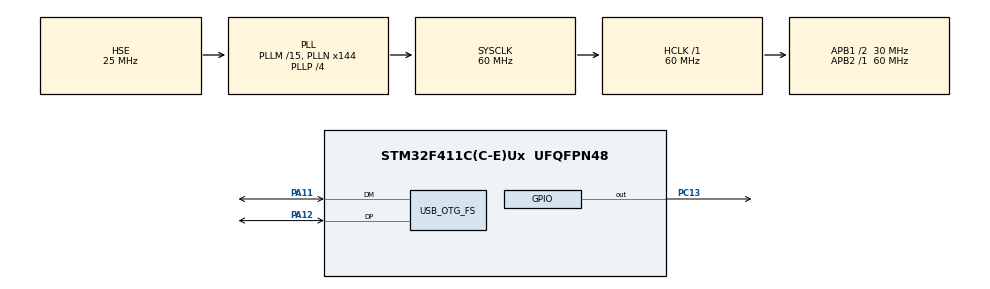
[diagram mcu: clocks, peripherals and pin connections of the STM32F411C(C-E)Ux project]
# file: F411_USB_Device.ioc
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Mcu.Family=STM32F4
Mcu.Name=STM32F411C(C-E)Ux
Mcu.Package=UFQFPN48
NVIC.OTG_FS_IRQn=true\:0\:0\:false\:false\:true\:false\:true\:true
NVIC.PriorityGroup=NVIC_PRIORITYGROUP_4
PA11.Mode=Device_Only
PA11.Signal=USB_OTG_FS_DM
PA12.Mode=Device_Only
PA12.Signal=USB_OTG_FS_DP
PC13-ANTI_TAMP.Signal=GPIO_Output
PH0\ -\ OSC_IN.Mode=HSE-External-Oscillator
PH0\ -\ OSC_IN.Signal=RCC_OSC_IN
PH1\ -\ OSC_OUT.Mode=HSE-External-Oscillator
PH1\ -\ OSC_OUT.Signal=RCC_OSC_OUT
ProjectManager.HeapSize=0x600
ProjectManager.StackSize=0x400
ProjectManager.TargetToolchain=STM32CubeIDE
RCC.48MHZClocksFreq_Value=48000000
RCC.AHBFreq_Value=60000000
RCC.APB1CLKDivider=RCC_HCLK_DIV2
RCC.APB1Freq_Value=30000000
RCC.APB1TimFreq_Value=60000000
RCC.APB2Freq_Value=60000000
RCC.APB2TimFreq_Value=60000000
RCC.CortexFreq_Value=60000000
RCC.HCLKFreq_Value=60000000
RCC.HSE_VALUE=25000000
RCC.HSI_VALUE=16000000
RCC.LSE_VALUE=32768
RCC.PLLM=15
RCC.PLLN=144
RCC.PLLP=RCC_PLLP_DIV4
RCC.PLLQ=5
RCC.SYSCLKFreq_VALUE=60000000
RCC.SYSCLKSource=RCC_SYSCLKSOURCE_PLLCLK
RCC.VCOOutputFreq_Value=240000000
USB_DEVICE.CLASS_NAME_FS=CDC
USB_DEVICE.VirtualMode=Cdc
USB_DEVICE.VirtualModeFS=Cdc_FS
USB_OTG_FS.VirtualMode=Device_Only
VP_USB_DEVICE_VS_USB_DEVICE_CDC_FS.Mode=CDC_FS
board=custom

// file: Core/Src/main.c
/* USER CODE BEGIN Header */
/**
 ******************************************************************************
 * @file           : main.c
 * @brief          : Main program body
 ******************************************************************************
 * @attention
 *
 * Copyright (c) 2025 STMicroelectronics.
 * All rights reserved.
 *
 * This software is licensed under terms that can be found in the LICENSE file
 * in the root directory of this software component.
 * If no LICENSE file comes with this software, it is provided AS-IS.
 *
 ******************************************************************************
 */
/* USER CODE END Header */
#include "main.h"
#include "usb_device.h"
#include "gpio.h"

/* USER CODE BEGIN Includes */
#include <string.h>
#include "usbd_cdc_if.h"
/* USER CODE END Includes */

void SystemClock_Config(void);

/* USER CODE BEGIN 0 */

/**********************************************
 * Fonction de traitement des données reçues
 **********************************************/
void My_USB_DataReceived_Handler(uint8_t *data, uint32_t length) {

	// Exemple : On retransmets les données.
	CDC_Transmit_FS(data, length);
}
/* USER CODE END 0 */

int main(void)
{

  /* MCU Configuration--------------------------------------------------------*/

  /* Reset of all peripherals, Initializes the Flash interface and the Systick. */
  HAL_Init();

  /* Configure the system clock */
  SystemClock_Config();

  /* Initialize all configured peripherals */
  MX_GPIO_Init();
  MX_USB_DEVICE_Init();
  /* USER CODE BEGIN 2 */
	// Enregistrer le callback pour traiter les données reçues
	USB_Register_DataReceived_Callback(My_USB_DataReceived_Handler);
  /* USER CODE END 2 */

  /* Infinite loop */
  /* USER CODE BEGIN WHILE */
	char testDataToSend[100];
	int counter = 0;

	while (1) {
    /* USER CODE END WHILE */

    /* USER CODE BEGIN 3 */
		HAL_Delay(1000);
		sprintf(testDataToSend, "Hello World %d\n\r", counter++);
		CDC_Transmit_FS((uint8_t*) testDataToSend, strlen(testDataToSend));

	}
  /* USER CODE END 3 */
}

void SystemClock_Config(void)
{
  RCC_OscInitTypeDef RCC_OscInitStruct = {0};
  RCC_ClkInitTypeDef RCC_ClkInitStruct = {0};

  /** Configure the main internal regulator output voltage
  */
  __HAL_RCC_PWR_CLK_ENABLE();
  __HAL_PWR_VOLTAGESCALING_CONFIG(PWR_REGULATOR_VOLTAGE_SCALE1);

  /** Initializes the RCC Oscillators according to the specified parameters
  * in the RCC_OscInitTypeDef structure.
  */
  RCC_OscInitStruct.OscillatorType = RCC_OSCILLATORTYPE_HSE;
  RCC_OscInitStruct.HSEState = RCC_HSE_ON;
  RCC_OscInitStruct.PLL.PLLState = RCC_PLL_ON;
  RCC_OscInitStruct.PLL.PLLSource = RCC_PLLSOURCE_HSE;
  RCC_OscInitStruct.PLL.PLLM = 15;
  RCC_OscInitStruct.PLL.PLLN = 144;
  RCC_OscInitStruct.PLL.PLLP = RCC_PLLP_DIV4;
  RCC_OscInitStruct.PLL.PLLQ = 5;
  if (HAL_RCC_OscConfig(&RCC_OscInitStruct) != HAL_OK)
  {
    Error_Handler();
  }

  /** Initializes the CPU, AHB and APB buses clocks
  */
  RCC_ClkInitStruct.ClockType = RCC_CLOCKTYPE_HCLK|RCC_CLOCKTYPE_SYSCLK
                              |RCC_CLOCKTYPE_PCLK1|RCC_CLOCKTYPE_PCLK2;
  RCC_ClkInitStruct.SYSCLKSource = RCC_SYSCLKSOURCE_PLLCLK;
  RCC_ClkInitStruct.AHBCLKDivider = RCC_SYSCLK_DIV1;
  RCC_ClkInitStruct.APB1CLKDivider = RCC_HCLK_DIV2;
  RCC_ClkInitStruct.APB2CLKDivider = RCC_HCLK_DIV1;

  if (HAL_RCC_ClockConfig(&RCC_ClkInitStruct, FLASH_LATENCY_1) != HAL_OK)
  {
    Error_Handler();
  }
}

void Error_Handler(void)
{
	__disable_irq();
	while (1) {
	}
}
